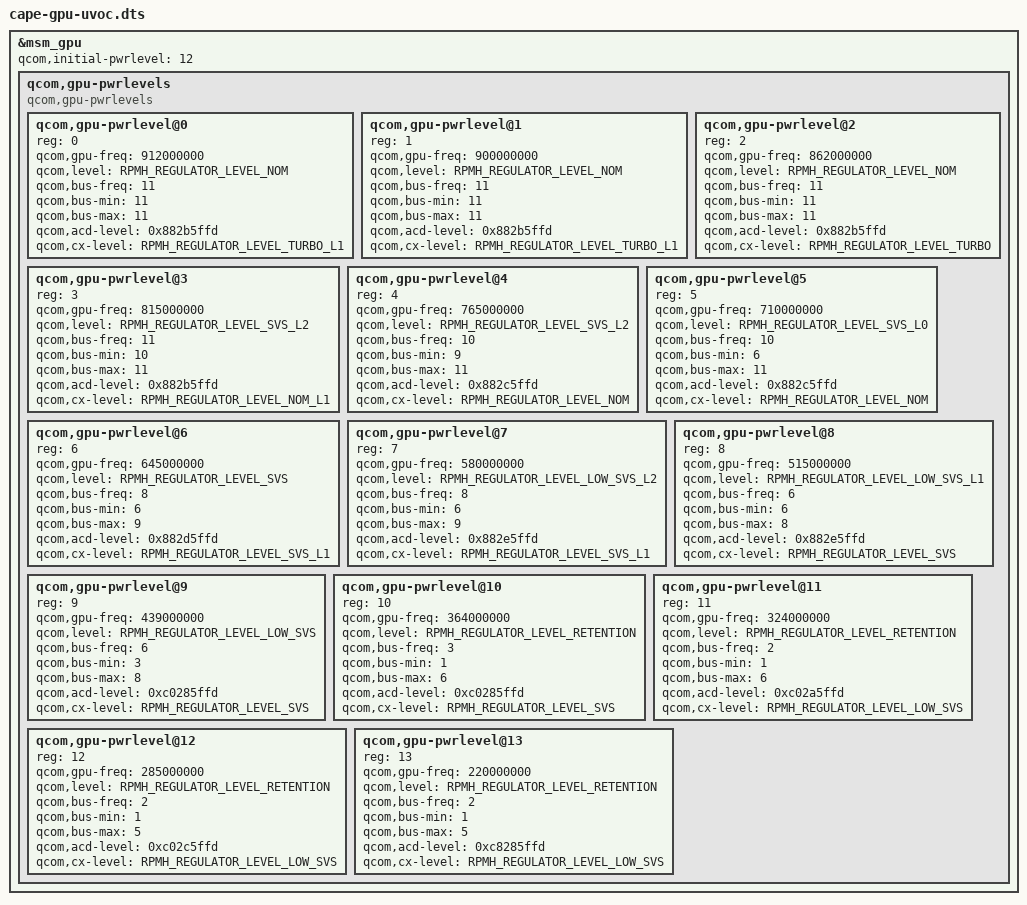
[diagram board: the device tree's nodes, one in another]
/*
 * DoraCore: cape.dtb with an Adreno 730 undervolt + overclock
 * power level table, from the KonaBess profile "Toniuvoc".
 * Generated by tools/gen-gpu-profiles.py; only the GPU (GX) rail
 * levels change, CX votes stay as stock. Running the GPU outside the
 * stock table may crash, freeze or damage the device.
 */

#include "cape.dts"

&msm_gpu {
	/delete-node/ qcom,gpu-pwrlevels;
};

&msm_gpu {
	qcom,initial-pwrlevel = <12>;

	qcom,gpu-pwrlevels {
		#address-cells = <1>;
		#size-cells = <0>;

		compatible = "qcom,gpu-pwrlevels";

		/* 912 MHz (not in stock) */
		qcom,gpu-pwrlevel@0 {
			reg = <0>;
			qcom,gpu-freq = <912000000>;
			qcom,level = <RPMH_REGULATOR_LEVEL_NOM>;

			qcom,bus-freq = <11>;
			qcom,bus-min = <11>;
			qcom,bus-max = <11>;

			qcom,acd-level = <0x882b5ffd>;
			qcom,cx-level = <RPMH_REGULATOR_LEVEL_TURBO_L1>;
		};

		/* 900 MHz (stock TURBO_L1) */
		qcom,gpu-pwrlevel@1 {
			reg = <1>;
			qcom,gpu-freq = <900000000>;
			qcom,level = <RPMH_REGULATOR_LEVEL_NOM>;

			qcom,bus-freq = <11>;
			qcom,bus-min = <11>;
			qcom,bus-max = <11>;

			qcom,acd-level = <0x882b5ffd>;
			qcom,cx-level = <RPMH_REGULATOR_LEVEL_TURBO_L1>;
		};

		/* 862 MHz (stock TURBO) */
		qcom,gpu-pwrlevel@2 {
			reg = <2>;
			qcom,gpu-freq = <862000000>;
			qcom,level = <RPMH_REGULATOR_LEVEL_NOM>;

			qcom,bus-freq = <11>;
			qcom,bus-min = <11>;
			qcom,bus-max = <11>;

			qcom,acd-level = <0x882b5ffd>;
			qcom,cx-level = <RPMH_REGULATOR_LEVEL_TURBO>;
		};

		/* 815 MHz (stock NOM_L1) */
		qcom,gpu-pwrlevel@3 {
			reg = <3>;
			qcom,gpu-freq = <815000000>;
			qcom,level = <RPMH_REGULATOR_LEVEL_SVS_L2>;

			qcom,bus-freq = <11>;
			qcom,bus-min = <10>;
			qcom,bus-max = <11>;

			qcom,acd-level = <0x882b5ffd>;
			qcom,cx-level = <RPMH_REGULATOR_LEVEL_NOM_L1>;
		};

		/* 765 MHz (stock NOM) */
		qcom,gpu-pwrlevel@4 {
			reg = <4>;
			qcom,gpu-freq = <765000000>;
			qcom,level = <RPMH_REGULATOR_LEVEL_SVS_L2>;

			qcom,bus-freq = <10>;
			qcom,bus-min = <9>;
			qcom,bus-max = <11>;

			qcom,acd-level = <0x882c5ffd>;
			qcom,cx-level = <RPMH_REGULATOR_LEVEL_NOM>;
		};

		/* 710 MHz (stock SVS_L2) */
		qcom,gpu-pwrlevel@5 {
			reg = <5>;
			qcom,gpu-freq = <710000000>;
			qcom,level = <RPMH_REGULATOR_LEVEL_SVS_L0>;

			qcom,bus-freq = <10>;
			qcom,bus-min = <6>;
			qcom,bus-max = <11>;

			qcom,acd-level = <0x882c5ffd>;
			qcom,cx-level = <RPMH_REGULATOR_LEVEL_NOM>;
		};

		/* 645 MHz (stock SVS_L1) */
		qcom,gpu-pwrlevel@6 {
			reg = <6>;
			qcom,gpu-freq = <645000000>;
			qcom,level = <RPMH_REGULATOR_LEVEL_SVS>;

			qcom,bus-freq = <8>;
			qcom,bus-min = <6>;
			qcom,bus-max = <9>;

			qcom,acd-level = <0x882d5ffd>;
			qcom,cx-level = <RPMH_REGULATOR_LEVEL_SVS_L1>;
		};

		/* 580 MHz (stock SVS_L0) */
		qcom,gpu-pwrlevel@7 {
			reg = <7>;
			qcom,gpu-freq = <580000000>;
			qcom,level = <RPMH_REGULATOR_LEVEL_LOW_SVS_L2>;

			qcom,bus-freq = <8>;
			qcom,bus-min = <6>;
			qcom,bus-max = <9>;

			qcom,acd-level = <0x882e5ffd>;
			qcom,cx-level = <RPMH_REGULATOR_LEVEL_SVS_L1>;
		};

		/* 515 MHz (stock SVS) */
		qcom,gpu-pwrlevel@8 {
			reg = <8>;
			qcom,gpu-freq = <515000000>;
			qcom,level = <RPMH_REGULATOR_LEVEL_LOW_SVS_L1>;

			qcom,bus-freq = <6>;
			qcom,bus-min = <6>;
			qcom,bus-max = <8>;

			qcom,acd-level = <0x882e5ffd>;
			qcom,cx-level = <RPMH_REGULATOR_LEVEL_SVS>;
		};

		/* 439 MHz (stock LOW_SVS_L2) */
		qcom,gpu-pwrlevel@9 {
			reg = <9>;
			qcom,gpu-freq = <439000000>;
			qcom,level = <RPMH_REGULATOR_LEVEL_LOW_SVS>;

			qcom,bus-freq = <6>;
			qcom,bus-min = <3>;
			qcom,bus-max = <8>;

			qcom,acd-level = <0xc0285ffd>;
			qcom,cx-level = <RPMH_REGULATOR_LEVEL_SVS>;
		};

		/* 364 MHz (stock LOW_SVS_L1) */
		qcom,gpu-pwrlevel@10 {
			reg = <10>;
			qcom,gpu-freq = <364000000>;
			qcom,level = <RPMH_REGULATOR_LEVEL_RETENTION>;

			qcom,bus-freq = <3>;
			qcom,bus-min = <1>;
			qcom,bus-max = <6>;

			qcom,acd-level = <0xc0285ffd>;
			qcom,cx-level = <RPMH_REGULATOR_LEVEL_SVS>;
		};

		/* 324 MHz (stock LOW_SVS) */
		qcom,gpu-pwrlevel@11 {
			reg = <11>;
			qcom,gpu-freq = <324000000>;
			qcom,level = <RPMH_REGULATOR_LEVEL_RETENTION>;

			qcom,bus-freq = <2>;
			qcom,bus-min = <1>;
			qcom,bus-max = <6>;

			qcom,acd-level = <0xc02a5ffd>;
			qcom,cx-level = <RPMH_REGULATOR_LEVEL_LOW_SVS>;
		};

		/* 285 MHz (stock LOW_SVS_D1) */
		qcom,gpu-pwrlevel@12 {
			reg = <12>;
			qcom,gpu-freq = <285000000>;
			qcom,level = <RPMH_REGULATOR_LEVEL_RETENTION>;

			qcom,bus-freq = <2>;
			qcom,bus-min = <1>;
			qcom,bus-max = <5>;

			qcom,acd-level = <0xc02c5ffd>;
			qcom,cx-level = <RPMH_REGULATOR_LEVEL_LOW_SVS>;
		};

		/* 220 MHz (stock MIN_SVS) */
		qcom,gpu-pwrlevel@13 {
			reg = <13>;
			qcom,gpu-freq = <220000000>;
			qcom,level = <RPMH_REGULATOR_LEVEL_RETENTION>;

			qcom,bus-freq = <2>;
			qcom,bus-min = <1>;
			qcom,bus-max = <5>;

			qcom,acd-level = <0xc8285ffd>;
			qcom,cx-level = <RPMH_REGULATOR_LEVEL_LOW_SVS>;
		};
	};
};
